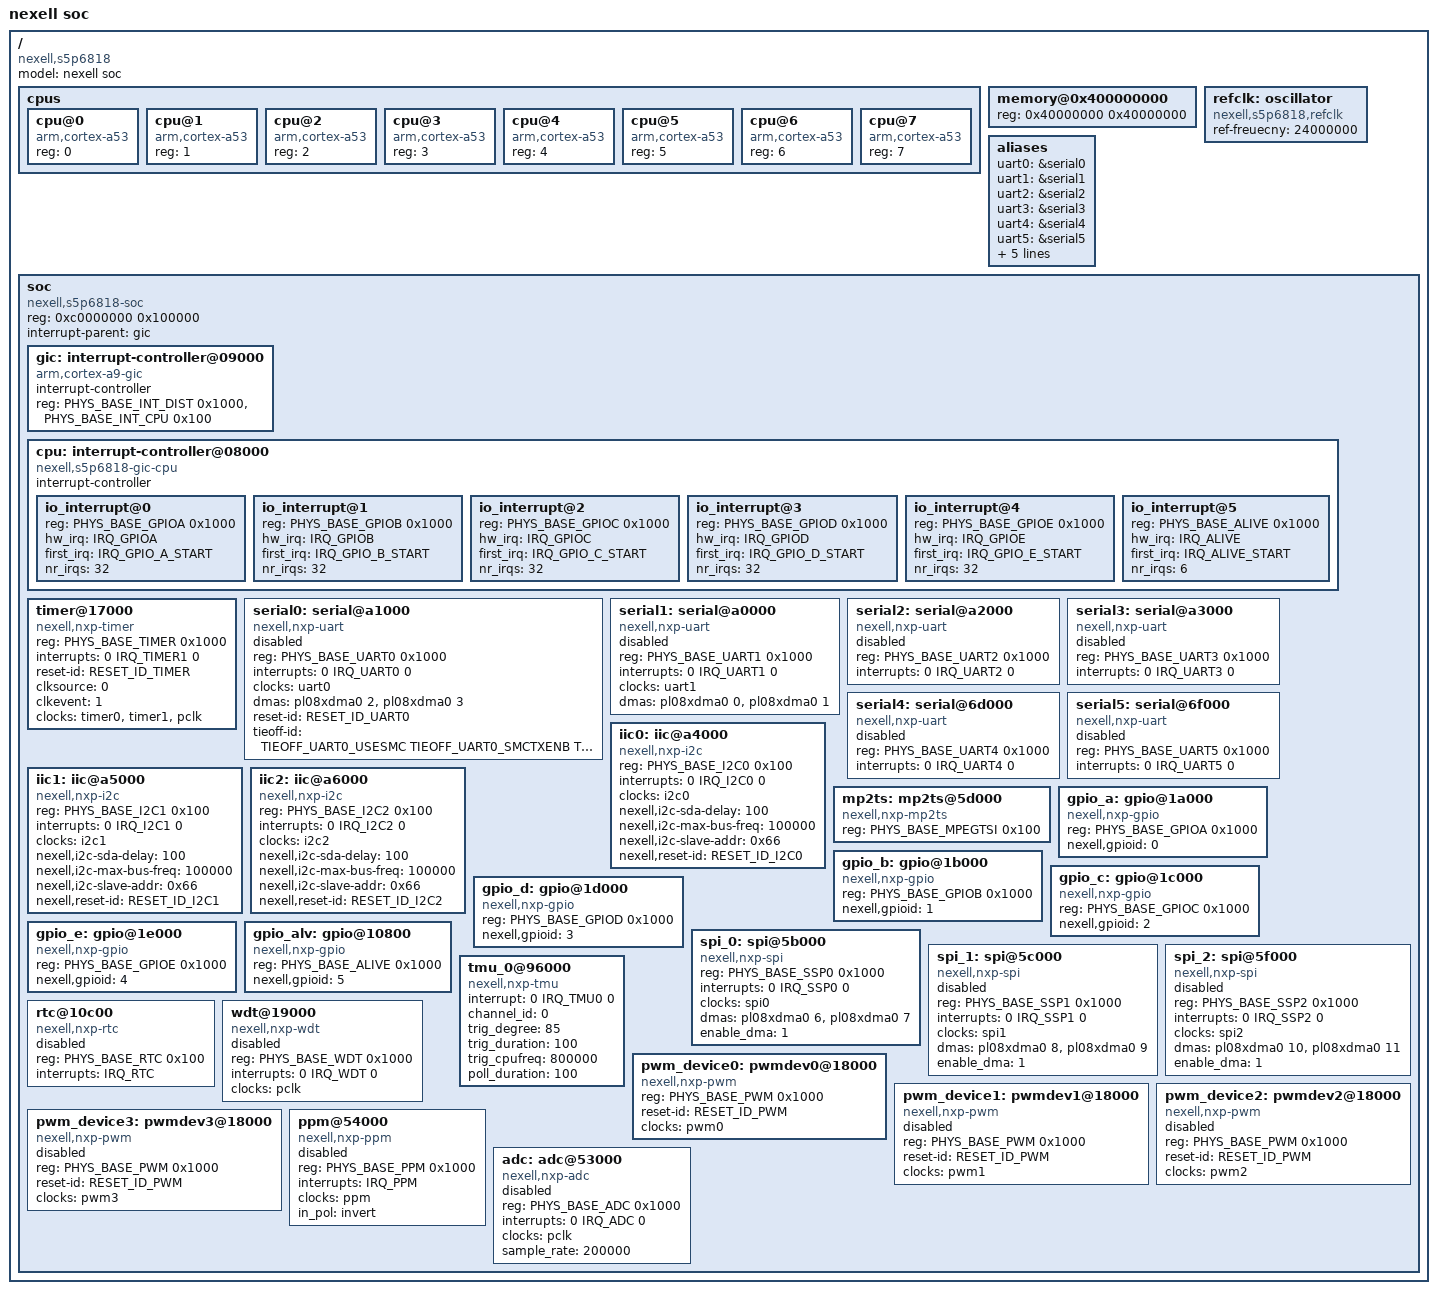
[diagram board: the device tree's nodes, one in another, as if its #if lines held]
/*
 * s5p6818.dtsi - Device Tree Include file for SLsiAp SoC
 *
 * Copyright 2009 Nexell Co.
 *		http://www.nexell.co.kr
 *
 * Licensed under GPLv2 or later.
 */

/dts-v1/;

#include "../skeleton.dtsi"

#include "../../../../../include/generated/autoconf.h"
#include "../../../../../include/nexell/s5p6818/s5p6818-base.h"
#include "../../../../../include/nexell/s5p6818/s5p6818-irq.h"

/ {
	model = "nexell soc";
	compatible = "nexell,s5p6818";
	#address-cells = <0x1>;
	#size-cells = <0x1>;

	cpus {
		#address-cells = <1>;
		#size-cells = <0>;

		cpu@0 {
			device_type = "cpu";
			compatible = "arm,cortex-a53";
			reg = <0>;
		};

		cpu@1 {
			device_type = "cpu";
			compatible = "arm,cortex-a53";
			reg = <1>;
		};

		cpu@2 {
			device_type = "cpu";
			compatible = "arm,cortex-a53";
			reg = <2>;
		};

		cpu@3 {
			device_type = "cpu";
			compatible = "arm,cortex-a53";
			reg = <3>;
		};

		cpu@4 {
			device_type = "cpu";
			compatible = "arm,cortex-a53";
			reg = <4>;
		};

		cpu@5 {
			device_type = "cpu";
			compatible = "arm,cortex-a53";
			reg = <5>;
		};

		cpu@6 {
			device_type = "cpu";
			compatible = "arm,cortex-a53";
			reg = <6>;
		};

		cpu@7 {
			device_type = "cpu";
			compatible = "arm,cortex-a53";
			reg = <7>;
		};
	};

	memory@0x400000000 {
		device_type = "memory";
		reg = <0x40000000 0x40000000>;
	};

	refclk: oscillator {
		compatible = "nexell,s5p6818,refclk";
		ref-freuecny = <24000000>;
	};

    aliases {
        uart0 = &serial0;
        uart1 = &serial1;
        uart2 = &serial2;
        uart3 = &serial3;
        uart4 = &serial4;
        uart5 = &serial5;
        spi0	= &spi_0;
        spi1	= &spi_1;
        spi2	= &spi_2;
		pwmdev0 = &pwm_device0;
		pwmdev1 = &pwm_device1;
		pwmdev1 = &pwm_device2;
		pwmdev1 = &pwm_device3;
    };

	soc {
		compatible = "nexell,s5p6818-soc", "simple-bus";
		#address-cells = <1>;
		#size-cells = <1>;
		reg = <0xc0000000 0x100000>;
		interrupt-parent = <&gic>;
		ranges;

		#include "s5p6818-soc.dtsi"

		gic:interrupt-controller@09000 {
			compatible = "arm,cortex-a9-gic";
			interrupt-controller;
			#interrupt-cells = <3>;
			reg	= <PHYS_BASE_INT_DIST 0x1000>, <PHYS_BASE_INT_CPU 0x100>;
		};

		cpu:interrupt-controller@08000 {
			compatible = "nexell,s5p6818-gic-cpu";
			interrupt-controller;
		  	#address-cells = <1>;
    	    #size-cells = <1>;
			ranges;

			io_interrupt@0 {
				device_type = "gpio";
				reg = <PHYS_BASE_GPIOA 0x1000>;
				hw_irq = <IRQ_GPIOA>;
				first_irq = <IRQ_GPIO_A_START>;
				nr_irqs = <32>;
			};

			io_interrupt@1 {
				device_type = "gpio";
				reg = <PHYS_BASE_GPIOB 0x1000>;
				hw_irq = <IRQ_GPIOB>;
				first_irq = <IRQ_GPIO_B_START>;
				nr_irqs = <32>;
			};

			io_interrupt@2 {
				device_type = "gpio";
				reg = <PHYS_BASE_GPIOC 0x1000>;
				hw_irq = <IRQ_GPIOC>;
				first_irq = <IRQ_GPIO_C_START>;
				nr_irqs = <32>;
			};

			io_interrupt@3 {
				device_type = "gpio";
				reg = <PHYS_BASE_GPIOD 0x1000>;
				hw_irq = <IRQ_GPIOD>;
				first_irq = <IRQ_GPIO_D_START>;
				nr_irqs = <32>;
			};

			io_interrupt@4 {
				device_type = "gpio";
				reg = <PHYS_BASE_GPIOE 0x1000>;
				hw_irq = <IRQ_GPIOE>;
				first_irq = <IRQ_GPIO_E_START>;
				nr_irqs = <32>;
			};

			io_interrupt@5 {
				device_type = "alive";
				reg = <PHYS_BASE_ALIVE 0x1000>;
				hw_irq = <IRQ_ALIVE>;
				first_irq = <IRQ_ALIVE_START>;
				nr_irqs = <6>;
			};
		};

		timer@17000 {
			compatible = "nexell,nxp-timer";
			reg = <PHYS_BASE_TIMER 0x1000>;
			interrupts = <0 IRQ_TIMER1 0>;
			reset-id = <RESET_ID_TIMER>;
			clksource = <0>;
			clkevent = <1>;
			clocks =  <&timer0>, <&timer1>, <&pclk>;
			clock-names = "timer0", "timer1", "pclk";
		};

		serial0:serial@a1000 {
			compatible = "nexell,nxp-uart";
			reg = <PHYS_BASE_UART0 0x1000>;
			interrupts = <0 IRQ_UART0 0>;
			clock-names = "uart0";
			clocks = <&uart0>;
			#if !defined(CONFIG_SERIAL_NXP_UART0)
			#if  defined(CONFIG_SERIAL_NXP_UART0_DMA)
			dma-names = "tx", "rx";
			dmas = <&pl08xdma0 2 &pl08xdma0 3>;
			#endif
			status = "disabled";
			#endif
			reset-id = <RESET_ID_UART0>;
			tieoff-id = <TIEOFF_UART0_USESMC TIEOFF_UART0_SMCTXENB TIEOFF_UART0_SMCRXENB>;
		};

		serial1:serial@a0000 {
			compatible = "nexell,nxp-uart";
			reg = <PHYS_BASE_UART1 0x1000>;
			interrupts = <0 IRQ_UART1 0>;
			clock-names = "uart1";
			clocks = <&uart1>;
			#if !defined(CONFIG_SERIAL_NXP_UART1)
			#if  defined(CONFIG_SERIAL_NXP_UART1_DMA)
			dma-names = "tx", "rx";
			dmas = <&pl08xdma0 0 &pl08xdma0 1>;
			#endif
			status = "disabled";
			#endif
		};

		serial2:serial@a2000 {
			compatible = "nexell,nxp-uart";
			reg = <PHYS_BASE_UART2 0x1000>;
			interrupts = <0 IRQ_UART2 0>;
			clock-names = "uart2";
			#if !defined(CONFIG_SERIAL_NXP_UART2)
			status = "disabled";
			#endif
		};

		serial3:serial@a3000 {
			compatible = "nexell,nxp-uart";
			reg = <PHYS_BASE_UART3 0x1000>;
			interrupts = <0 IRQ_UART3 0>;
			clock-names = "uart3";
			#if !defined(CONFIG_SERIAL_NXP_UART3)
			status = "disabled";
			#endif
		};

		serial4:serial@6d000 {
			compatible = "nexell,nxp-uart";
			reg = <PHYS_BASE_UART4 0x1000>;
			interrupts = <0 IRQ_UART4 0>;
			clock-names = "uart4";
			#if !defined(CONFIG_SERIAL_NXP_UART4)
			status = "disabled";
			#endif
		};

		serial5:serial@6f000 {
			compatible = "nexell,nxp-uart";
			reg = <PHYS_BASE_UART5 0x1000>;
			interrupts = <0 IRQ_UART5 0>;
			clock-names = "uart5";
			#if !defined(CONFIG_SERIAL_NXP_UART5)
			status = "disabled";
			#endif
		};

	    iic0:iic@a4000 {
			compatible = "nexell,nxp-i2c";
			reg = <PHYS_BASE_I2C0 0x100>;
			interrupts = <0 IRQ_I2C0 0>;
			clock-names = "i2c0";
			clocks = <&i2c0>;
			nexell,i2c-sda-delay = <100>;
			nexell,i2c-max-bus-freq = <100000>;
			nexell,i2c-slave-addr = <0x66>;
			nexell,reset-id = <RESET_ID_I2C0>;
		};
	    iic1:iic@a5000 {
			compatible = "nexell,nxp-i2c";
			reg = <PHYS_BASE_I2C1 0x100>;
			interrupts = <0 IRQ_I2C1 0>;
			clock-names = "i2c1";
			clocks = <&i2c1>;
			nexell,i2c-sda-delay = <100>;
			nexell,i2c-max-bus-freq = <100000>;
			nexell,i2c-slave-addr = <0x66>;
			nexell,reset-id = <RESET_ID_I2C1>;
		};

	    iic2:iic@a6000 {
			compatible = "nexell,nxp-i2c";
			reg = <PHYS_BASE_I2C2 0x100>;
			interrupts = <0 IRQ_I2C2 0>;
			clock-names = "i2c2";
			clocks = <&i2c2>;
			nexell,i2c-sda-delay = <100>;
			nexell,i2c-max-bus-freq = <100000>;
			nexell,i2c-slave-addr = <0x66>;
			nexell,reset-id = <RESET_ID_I2C2>;
		};

		mp2ts:mp2ts@5d000 {
			compatible = "nexell,nxp-mp2ts";
			reg = <PHYS_BASE_MPEGTSI 0x100>;
		};
		
		gpio_a:gpio@1a000 {
			compatible = "nexell,nxp-gpio";		
			reg = <PHYS_BASE_GPIOA 0x1000>;
			nexell,gpioid = <0>;
		};
		gpio_b:gpio@1b000 {
			compatible = "nexell,nxp-gpio";		
			reg = <PHYS_BASE_GPIOB 0x1000>;
			nexell,gpioid = <1>;
		};
		gpio_c:gpio@1c000 {
			compatible = "nexell,nxp-gpio";		
			reg = <PHYS_BASE_GPIOC 0x1000>;
			nexell,gpioid = <2>;
		};
		gpio_d:gpio@1d000 {
			compatible = "nexell,nxp-gpio";		
			reg = <PHYS_BASE_GPIOD 0x1000>;
			nexell,gpioid = <3>;
		};
		gpio_e:gpio@1e000 {
			compatible = "nexell,nxp-gpio";		
			reg = <PHYS_BASE_GPIOE 0x1000>;
			nexell,gpioid = <4>;
		};
		gpio_alv:gpio@10800 {
			compatible = "nexell,nxp-gpio";		
			reg = <PHYS_BASE_ALIVE 0x1000>;
			nexell,gpioid = <5>;
		};
		
		spi_0:spi@5b000 {
			compatible = "nexell,nxp-spi";
			reg = <PHYS_BASE_SSP0 0x1000>;
			interrupts	= <0 IRQ_SSP0 0>;
			clock-names = "spi0";
			clocks = <&spi0>;
			dma-names = "tx", "rx";
			dmas = <&pl08xdma0 6 &pl08xdma0 7>;
			enable_dma = <1>;
		};
		
		
		spi_1:spi@5c000 {
			compatible = "nexell,nxp-spi";
			reg = <PHYS_BASE_SSP1 0x1000>;
			interrupts	= <0 IRQ_SSP1 0>;
			clock-names = "spi1";
			clocks = <&spi1>;
			dma-names = "tx", "rx";
			dmas = <&pl08xdma0 8 &pl08xdma0 9>;
			enable_dma = <1>;
			status = "disabled";
		};
		
		
		spi_2:spi@5f000 {
			compatible = "nexell,nxp-spi";
			reg = <PHYS_BASE_SSP2 0x1000>;
			interrupts	= <0 IRQ_SSP2 0>;
			clock-names = "spi2";
			clocks = <&spi2>;
			dma-names = "tx", "rx";
			dmas = <&pl08xdma0 10 &pl08xdma0 11>;
			enable_dma = <1>;
			status = "disabled";
		};
		
		tmu_0@96000 {
			compatible = "nexell,nxp-tmu";
			interrupt = <0 IRQ_TMU0 0>;
			channel_id    = <0>;
			trig_degree   = <85>;
			trig_duration = <100>;
			trig_cpufreq  = <800000>;
			poll_duration = <100>;
		};

		rtc@10c00 {
			compatible = "nexell,nxp-rtc";
			reg = <PHYS_BASE_RTC 0x100>;
			interrupts = <IRQ_RTC>;
			status = "disabled";
		};

		wdt@19000 {
			compatible = "nexell,nxp-wdt";
			reg = <PHYS_BASE_WDT 0x1000>;
			interrupts = <0 IRQ_WDT 0>;
			clock-names = "pclk";
			clocks = <&pclk>;
			status = "disabled";
		};

		pwm_device0:pwmdev0@18000 {
			compatible = "nexell,nxp-pwm";
			reg = <PHYS_BASE_PWM 0x1000>;
			#pwm-cells = <2>;
			reset-id = <RESET_ID_PWM>;
			clock-names = "pwm0";
			clocks =  <&pwm0>;
			status = "okay";
		};

		pwm_device1:pwmdev1@18000 {
			compatible = "nexell,nxp-pwm";
			reg = <PHYS_BASE_PWM 0x1000>;
			#pwm-cells = <2>;
			reset-id = <RESET_ID_PWM>;
			clock-names = "pwm1";
			clocks =  <&pwm1>;
			status = "disabled";
		};
		pwm_device2:pwmdev2@18000 {
			compatible = "nexell,nxp-pwm";
			reg = <PHYS_BASE_PWM 0x1000>;
			#pwm-cells = <2>;
			reset-id = <RESET_ID_PWM>;
			clock-names = "pwm2";
			clocks =  <&pwm2>;
			status = "disabled";
		};
		pwm_device3:pwmdev3@18000 {
			compatible = "nexell,nxp-pwm";
			reg = <PHYS_BASE_PWM 0x1000>;
			#pwm-cells = <2>;
			reset-id = <RESET_ID_PWM>;
			clock-names = "pwm3";
			clocks =  <&pwm3>;
			status = "disabled";
		};

		ppm@54000 {
			compatible = "nexell,nxp-ppm";
			reg = <PHYS_BASE_PPM 0x1000>;
			interrupts = <IRQ_PPM>;
			clock-names = "ppm";
			clocks = <&ppm>;
			in_pol = "invert";
			status = "disabled";
		};

		adc:adc@53000 {
			compatible = "nexell,nxp-adc";
			reg = <PHYS_BASE_ADC 0x1000>;
			interrupts = <0 IRQ_ADC 0>;
			clocks = <&pclk>;
			clock-names = "sys-bpclk";
			sample_rate = <200000>;
			#io-channel-cells = <1>;
			status = "disabled";
		};
	};
	
};
